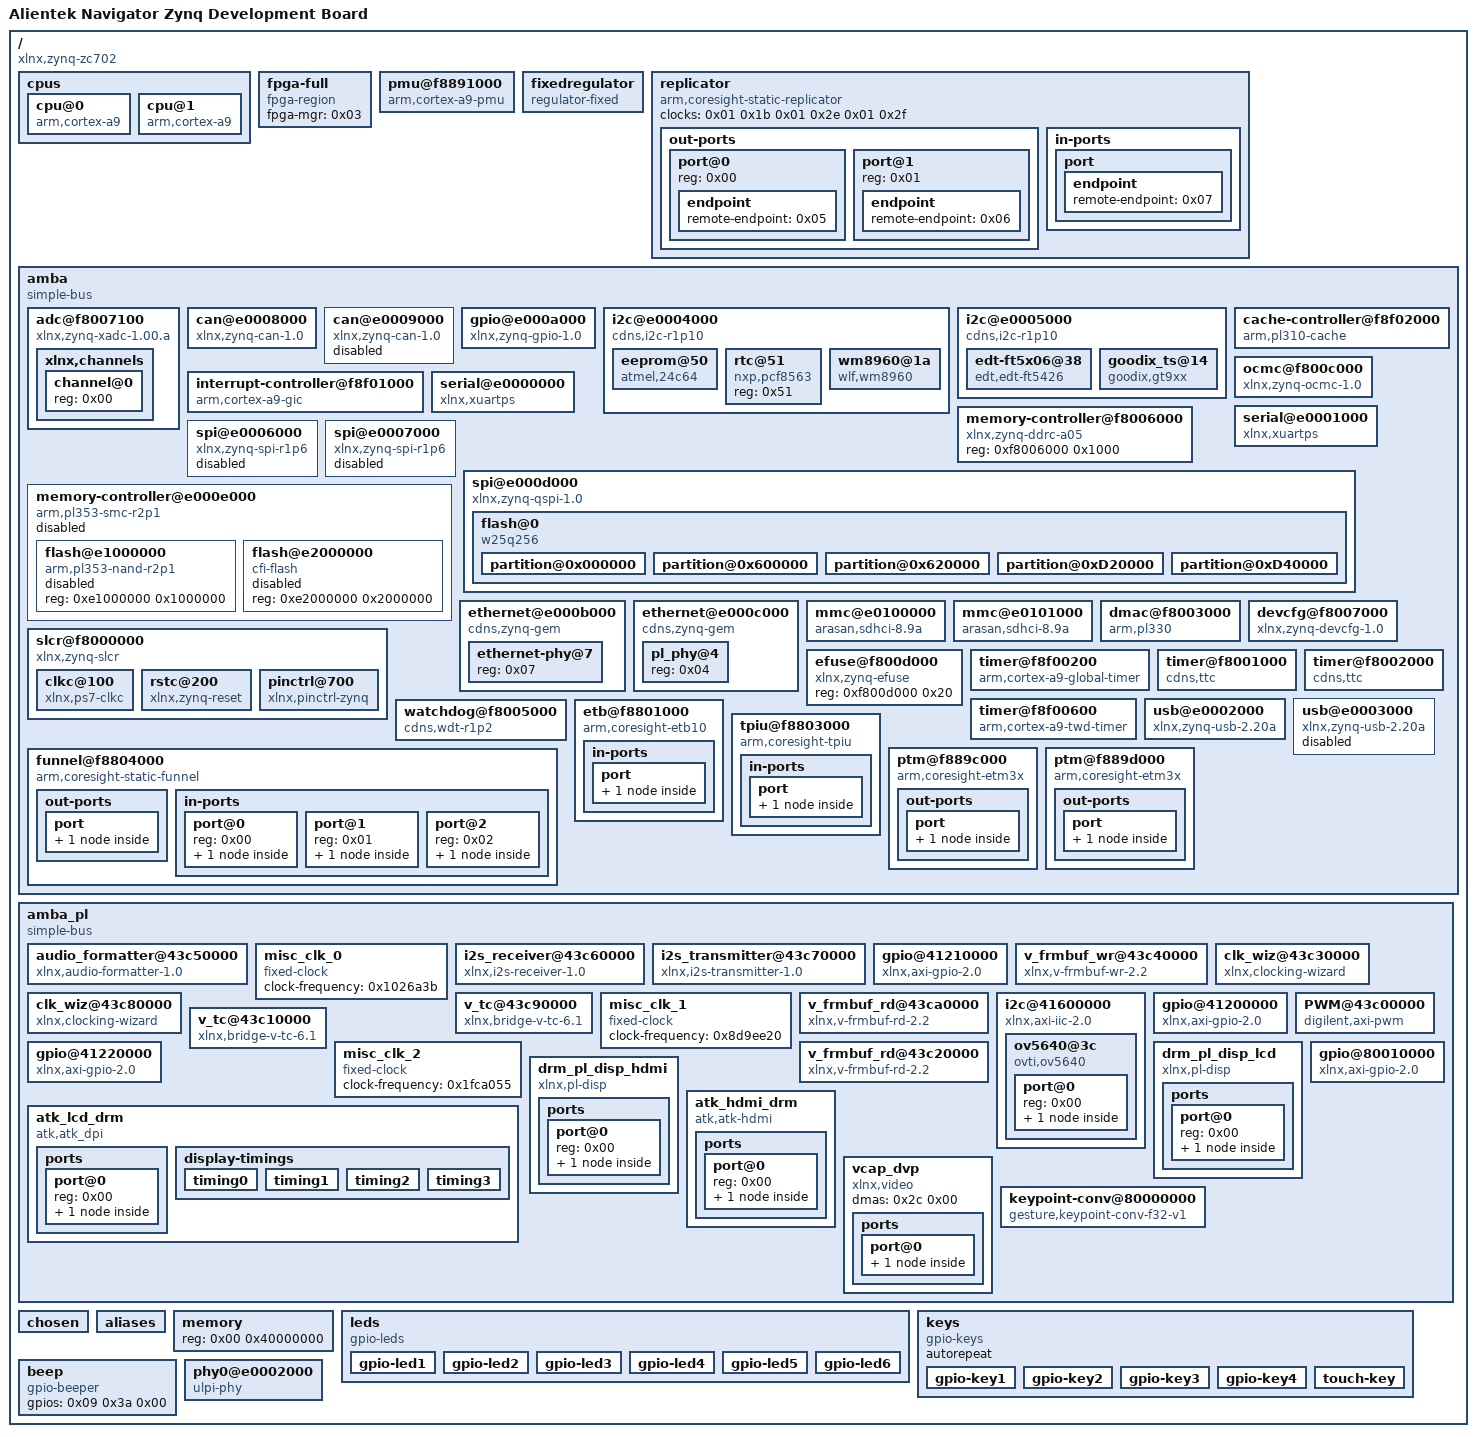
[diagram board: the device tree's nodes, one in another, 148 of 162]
/dts-v1/;

/ {
	#address-cells = <0x01>;
	#size-cells = <0x01>;
	compatible = "xlnx,zynq-zc702\0xlnx,zynq-7000";
	model = "Alientek Navigator Zynq Development Board";

	cpus {
		#address-cells = <0x01>;
		#size-cells = <0x00>;

		cpu@0 {
			compatible = "arm,cortex-a9";
			device_type = "cpu";
			reg = <0x00>;
			clocks = <0x01 0x03>;
			clock-latency = <0x3e8>;
			cpu0-supply = <0x02>;
			operating-points = <0xbb2ca 0xf4240 0x5d965 0xf4240>;
			phandle = <0x13>;
		};

		cpu@1 {
			compatible = "arm,cortex-a9";
			device_type = "cpu";
			reg = <0x01>;
			clocks = <0x01 0x03>;
			phandle = <0x15>;
		};
	};

	fpga-full {
		compatible = "fpga-region";
		fpga-mgr = <0x03>;
		#address-cells = <0x01>;
		#size-cells = <0x01>;
		ranges;
		phandle = <0x2f>;
	};

	pmu@f8891000 {
		compatible = "arm,cortex-a9-pmu";
		interrupts = <0x00 0x05 0x04 0x00 0x06 0x04>;
		interrupt-parent = <0x04>;
		reg = <0xf8891000 0x1000 0xf8893000 0x1000>;
	};

	fixedregulator {
		compatible = "regulator-fixed";
		regulator-name = "VCCPINT";
		regulator-min-microvolt = <0xf4240>;
		regulator-max-microvolt = <0xf4240>;
		regulator-boot-on;
		regulator-always-on;
		phandle = <0x02>;
	};

	replicator {
		compatible = "arm,coresight-static-replicator";
		clocks = <0x01 0x1b 0x01 0x2e 0x01 0x2f>;
		clock-names = "apb_pclk\0dbg_trc\0dbg_apb";

		out-ports {
			#address-cells = <0x01>;
			#size-cells = <0x00>;

			port@0 {
				reg = <0x00>;

				endpoint {
					remote-endpoint = <0x05>;
					phandle = <0x0f>;
				};
			};

			port@1 {
				reg = <0x01>;

				endpoint {
					remote-endpoint = <0x06>;
					phandle = <0x0e>;
				};
			};
		};

		in-ports {

			port {

				endpoint {
					remote-endpoint = <0x07>;
					phandle = <0x10>;
				};
			};
		};
	};

	amba {
		u-boot,dm-pre-reloc;
		compatible = "simple-bus";
		#address-cells = <0x01>;
		#size-cells = <0x01>;
		interrupt-parent = <0x04>;
		ranges;
		phandle = <0x30>;

		adc@f8007100 {
			compatible = "xlnx,zynq-xadc-1.00.a";
			reg = <0xf8007100 0x20>;
			interrupts = <0x00 0x07 0x04>;
			interrupt-parent = <0x04>;
			clocks = <0x01 0x0c>;
			status = "okay";
			phandle = <0x31>;

			xlnx,channels {
				#address-cells = <0x01>;
				#size-cells = <0x00>;

				channel@0 {
					reg = <0x00>;
				};
			};
		};

		can@e0008000 {
			compatible = "xlnx,zynq-can-1.0";
			status = "okay";
			clocks = <0x01 0x13 0x01 0x24>;
			clock-names = "can_clk\0pclk";
			reg = <0xe0008000 0x1000>;
			interrupts = <0x00 0x1c 0x04>;
			interrupt-parent = <0x04>;
			tx-fifo-depth = <0x40>;
			rx-fifo-depth = <0x40>;
			phandle = <0x32>;
		};

		can@e0009000 {
			compatible = "xlnx,zynq-can-1.0";
			status = "disabled";
			clocks = <0x01 0x14 0x01 0x25>;
			clock-names = "can_clk\0pclk";
			reg = <0xe0009000 0x1000>;
			interrupts = <0x00 0x33 0x04>;
			interrupt-parent = <0x04>;
			tx-fifo-depth = <0x40>;
			rx-fifo-depth = <0x40>;
			phandle = <0x33>;
		};

		gpio@e000a000 {
			compatible = "xlnx,zynq-gpio-1.0";
			#gpio-cells = <0x02>;
			clocks = <0x01 0x2a>;
			gpio-controller;
			interrupt-controller;
			#interrupt-cells = <0x02>;
			interrupt-parent = <0x04>;
			interrupts = <0x00 0x14 0x04>;
			reg = <0xe000a000 0x1000>;
			emio-gpio-width = <0x0b>;
			gpio-mask-high = <0x00>;
			gpio-mask-low = <0x5600>;
			phandle = <0x09>;
		};

		i2c@e0004000 {
			compatible = "cdns,i2c-r1p10";
			status = "okay";
			clocks = <0x01 0x26>;
			interrupt-parent = <0x04>;
			interrupts = <0x00 0x19 0x04>;
			reg = <0xe0004000 0x1000>;
			#address-cells = <0x01>;
			#size-cells = <0x00>;
			clock-frequency = <0x186a0>;
			phandle = <0x34>;

			eeprom@50 {
				compatible = "atmel,24c64";
				reg = <0x50>;
				pagesize = <0x20>;
			};

			rtc@51 {
				compatible = "nxp,pcf8563";
				reg = <0x51>;
			};

			wm8960@1a {
				compatible = "wlf,wm8960";
				reg = <0x1a>;
				#sound-dai-cells = <0x00>;
				wlf,shared-lrclk;
				clock-names = "mclk";
				clocks = <0x08 0x01>;
				phandle = <0x1a>;
			};
		};

		i2c@e0005000 {
			compatible = "cdns,i2c-r1p10";
			status = "okay";
			clocks = <0x01 0x27>;
			interrupt-parent = <0x04>;
			interrupts = <0x00 0x30 0x04>;
			reg = <0xe0005000 0x1000>;
			#address-cells = <0x01>;
			#size-cells = <0x00>;
			clock-frequency = <0x186a0>;
			phandle = <0x2a>;

			edt-ft5x06@38 {
				compatible = "edt,edt-ft5426";
				reg = <0x38>;
				interrupt-parent = <0x09>;
				interrupts = <0x3c 0x02>;
				reset-gpio = <0x09 0x3b 0x01>;
				interrupt-gpio = <0x09 0x3c 0x01>;
			};

			goodix_ts@14 {
				compatible = "goodix,gt9xx";
				status = "okay";
				reg = <0x14>;
				interrupt-parent = <0x09>;
				interrupts = <0x3c 0x00>;
				reset-gpio = <0x09 0x3b 0x01>;
				interrupt-gpio = <0x09 0x3c 0x01>;
			};
		};

		interrupt-controller@f8f01000 {
			compatible = "arm,cortex-a9-gic";
			#interrupt-cells = <0x03>;
			interrupt-controller;
			reg = <0xf8f01000 0x1000 0xf8f00100 0x100>;
			num_cpus = <0x02>;
			num_interrupts = <0x60>;
			phandle = <0x04>;
		};

		cache-controller@f8f02000 {
			compatible = "arm,pl310-cache";
			reg = <0xf8f02000 0x1000>;
			interrupts = <0x00 0x02 0x04>;
			arm,data-latency = <0x03 0x02 0x02>;
			arm,tag-latency = <0x02 0x02 0x02>;
			cache-unified;
			cache-level = <0x02>;
			phandle = <0x35>;
		};

		memory-controller@f8006000 {
			compatible = "xlnx,zynq-ddrc-a05";
			reg = <0xf8006000 0x1000>;
			phandle = <0x36>;
		};

		ocmc@f800c000 {
			compatible = "xlnx,zynq-ocmc-1.0";
			interrupt-parent = <0x04>;
			interrupts = <0x00 0x03 0x04>;
			reg = <0xf800c000 0x1000>;
			phandle = <0x37>;
		};

		serial@e0000000 {
			compatible = "xlnx,xuartps\0cdns,uart-r1p8";
			status = "okay";
			clocks = <0x01 0x17 0x01 0x28>;
			clock-names = "uart_clk\0pclk";
			reg = <0xe0000000 0x1000>;
			interrupts = <0x00 0x1b 0x04>;
			cts-override;
			device_type = "serial";
			port-number = <0x00>;
			u-boot,dm-pre-reloc;
			phandle = <0x38>;
		};

		serial@e0001000 {
			compatible = "xlnx,xuartps\0cdns,uart-r1p8";
			status = "okay";
			clocks = <0x01 0x18 0x01 0x29>;
			clock-names = "uart_clk\0pclk";
			reg = <0xe0001000 0x1000>;
			interrupts = <0x00 0x32 0x04>;
			cts-override;
			device_type = "serial";
			port-number = <0x01>;
			phandle = <0x39>;
		};

		spi@e0006000 {
			compatible = "xlnx,zynq-spi-r1p6";
			reg = <0xe0006000 0x1000>;
			status = "disabled";
			interrupt-parent = <0x04>;
			interrupts = <0x00 0x1a 0x04>;
			clocks = <0x01 0x19 0x01 0x22>;
			clock-names = "ref_clk\0pclk";
			#address-cells = <0x01>;
			#size-cells = <0x00>;
			phandle = <0x3a>;
		};

		spi@e0007000 {
			compatible = "xlnx,zynq-spi-r1p6";
			reg = <0xe0007000 0x1000>;
			status = "disabled";
			interrupt-parent = <0x04>;
			interrupts = <0x00 0x31 0x04>;
			clocks = <0x01 0x1a 0x01 0x23>;
			clock-names = "ref_clk\0pclk";
			#address-cells = <0x01>;
			#size-cells = <0x00>;
			phandle = <0x3b>;
		};

		spi@e000d000 {
			clock-names = "ref_clk\0pclk";
			clocks = <0x01 0x0a 0x01 0x2b>;
			compatible = "xlnx,zynq-qspi-1.0";
			status = "okay";
			interrupt-parent = <0x04>;
			interrupts = <0x00 0x13 0x04>;
			reg = <0xe000d000 0x1000>;
			#address-cells = <0x01>;
			#size-cells = <0x00>;
			is-dual = <0x00>;
			num-cs = <0x01>;
			spi-rx-bus-width = <0x04>;
			spi-tx-bus-width = <0x04>;
			u-boot,dm-pre-reloc;
			phandle = <0x3c>;

			flash@0 {
				compatible = "w25q256\0jedec,spi-nor";
				reg = <0x00>;
				spi-max-frequency = <0x2faf080>;
				#address-cells = <0x01>;
				#size-cells = <0x01>;

				partition@0x000000 {
					label = "boot";
					reg = <0x00 0x600000>;
				};

				partition@0x600000 {
					label = "bootenv";
					reg = <0x600000 0x20000>;
				};

				partition@0x620000 {
					label = "image.ub";
					reg = <0x620000 0x700000>;
				};

				partition@0xD20000 {
					label = "boot.scr";
					reg = <0xd20000 0x20000>;
				};

				partition@0xD40000 {
					label = "space";
					reg = <0xd40000 0x00>;
				};
			};
		};

		memory-controller@e000e000 {
			#address-cells = <0x01>;
			#size-cells = <0x01>;
			status = "disabled";
			clock-names = "memclk\0apb_pclk";
			clocks = <0x01 0x0b 0x01 0x2c>;
			compatible = "arm,pl353-smc-r2p1\0arm,primecell";
			interrupt-parent = <0x04>;
			interrupts = <0x00 0x12 0x04>;
			ranges;
			reg = <0xe000e000 0x1000>;
			phandle = <0x3d>;

			flash@e1000000 {
				status = "disabled";
				compatible = "arm,pl353-nand-r2p1";
				reg = <0xe1000000 0x1000000>;
				#address-cells = <0x01>;
				#size-cells = <0x01>;
				phandle = <0x3e>;
			};

			flash@e2000000 {
				status = "disabled";
				compatible = "cfi-flash";
				reg = <0xe2000000 0x2000000>;
				#address-cells = <0x01>;
				#size-cells = <0x01>;
				phandle = <0x3f>;
			};
		};

		ethernet@e000b000 {
			compatible = "cdns,zynq-gem\0cdns,gem";
			reg = <0xe000b000 0x1000>;
			status = "okay";
			interrupts = <0x00 0x16 0x04>;
			clocks = <0x01 0x1e 0x01 0x1e 0x01 0x0d>;
			clock-names = "pclk\0hclk\0tx_clk";
			#address-cells = <0x01>;
			#size-cells = <0x00>;
			phy-mode = "rgmii-id";
			xlnx,ptp-enet-clock = <0x79dbbf3>;
			local-mac-address = [00 0a 35 00 8b 87];
			phy-handle = <0x0a>;
			phandle = <0x40>;

			ethernet-phy@7 {
				reg = <0x07>;
				device_type = "ethernet-phy";
				phandle = <0x0a>;
			};
		};

		ethernet@e000c000 {
			compatible = "cdns,zynq-gem\0cdns,gem";
			reg = <0xe000c000 0x1000>;
			status = "okay";
			interrupts = <0x00 0x2d 0x04>;
			clocks = <0x01 0x1f 0x01 0x1f 0x01 0x0e>;
			clock-names = "pclk\0hclk\0tx_clk";
			#address-cells = <0x01>;
			#size-cells = <0x00>;
			phy-mode = "gmii";
			xlnx,ptp-enet-clock = <0x79dbbf3>;
			local-mac-address = [00 0a 35 00 11 55];
			phy-reset-gpio = <0x09 0x3f 0x01>;
			phy-reset-active-low;
			phy-handle = <0x0b>;
			phandle = <0x41>;

			pl_phy@4 {
				reg = <0x04>;
				device_type = "ethernet-phy";
				phandle = <0x0b>;
			};
		};

		mmc@e0100000 {
			compatible = "arasan,sdhci-8.9a";
			status = "okay";
			clock-names = "clk_xin\0clk_ahb";
			clocks = <0x01 0x15 0x01 0x20>;
			interrupt-parent = <0x04>;
			interrupts = <0x00 0x18 0x04>;
			reg = <0xe0100000 0x1000>;
			xlnx,has-cd = <0x01>;
			xlnx,has-power = <0x00>;
			xlnx,has-wp = <0x00>;
			u-boot,dm-pre-reloc;
			phandle = <0x42>;
		};

		mmc@e0101000 {
			compatible = "arasan,sdhci-8.9a";
			status = "okay";
			clock-names = "clk_xin\0clk_ahb";
			clocks = <0x01 0x16 0x01 0x21>;
			interrupt-parent = <0x04>;
			interrupts = <0x00 0x2f 0x04>;
			reg = <0xe0101000 0x1000>;
			xlnx,has-cd = <0x00>;
			xlnx,has-power = <0x00>;
			xlnx,has-wp = <0x00>;
			phandle = <0x43>;
		};

		slcr@f8000000 {
			u-boot,dm-pre-reloc;
			#address-cells = <0x01>;
			#size-cells = <0x01>;
			compatible = "xlnx,zynq-slcr\0syscon\0simple-mfd";
			reg = <0xf8000000 0x1000>;
			ranges;
			phandle = <0x0c>;

			clkc@100 {
				u-boot,dm-pre-reloc;
				#clock-cells = <0x01>;
				compatible = "xlnx,ps7-clkc";
				fclk-enable = <0x07>;
				clock-output-names = "armpll\0ddrpll\0iopll\0cpu_6or4x\0cpu_3or2x\0cpu_2x\0cpu_1x\0ddr2x\0ddr3x\0dci\0lqspi\0smc\0pcap\0gem0\0gem1\0fclk0\0fclk1\0fclk2\0fclk3\0can0\0can1\0sdio0\0sdio1\0uart0\0uart1\0spi0\0spi1\0dma\0usb0_aper\0usb1_aper\0gem0_aper\0gem1_aper\0sdio0_aper\0sdio1_aper\0spi0_aper\0spi1_aper\0can0_aper\0can1_aper\0i2c0_aper\0i2c1_aper\0uart0_aper\0uart1_aper\0gpio_aper\0lqspi_aper\0smc_aper\0swdt\0dbg_trc\0dbg_apb";
				reg = <0x100 0x100>;
				ps-clk-frequency = <0x1fca055>;
				phandle = <0x01>;
			};

			rstc@200 {
				compatible = "xlnx,zynq-reset";
				reg = <0x200 0x48>;
				#reset-cells = <0x01>;
				syscon = <0x0c>;
				phandle = <0x44>;
			};

			pinctrl@700 {
				compatible = "xlnx,pinctrl-zynq";
				reg = <0x700 0x200>;
				syscon = <0x0c>;
				phandle = <0x45>;
			};
		};

		dmac@f8003000 {
			compatible = "arm,pl330\0arm,primecell";
			reg = <0xf8003000 0x1000>;
			interrupt-parent = <0x04>;
			interrupt-names = "abort\0dma0\0dma1\0dma2\0dma3\0dma4\0dma5\0dma6\0dma7";
			interrupts = <0x00 0x0d 0x04 0x00 0x0e 0x04 0x00 0x0f 0x04 0x00 0x10 0x04 0x00 0x11 0x04 0x00 0x28 0x04 0x00 0x29 0x04 0x00 0x2a 0x04 0x00 0x2b 0x04>;
			#dma-cells = <0x01>;
			#dma-channels = <0x08>;
			#dma-requests = <0x04>;
			clocks = <0x01 0x1b>;
			clock-names = "apb_pclk";
			phandle = <0x46>;
		};

		devcfg@f8007000 {
			compatible = "xlnx,zynq-devcfg-1.0";
			interrupt-parent = <0x04>;
			interrupts = <0x00 0x08 0x04>;
			reg = <0xf8007000 0x100>;
			clocks = <0x01 0x0c 0x01 0x0f 0x01 0x10 0x01 0x11 0x01 0x12>;
			clock-names = "ref_clk\0fclk0\0fclk1\0fclk2\0fclk3";
			syscon = <0x0c>;
			phandle = <0x03>;
		};

		efuse@f800d000 {
			compatible = "xlnx,zynq-efuse";
			reg = <0xf800d000 0x20>;
			phandle = <0x47>;
		};

		timer@f8f00200 {
			compatible = "arm,cortex-a9-global-timer";
			reg = <0xf8f00200 0x20>;
			interrupts = <0x01 0x0b 0x301>;
			interrupt-parent = <0x04>;
			clocks = <0x01 0x04>;
			phandle = <0x48>;
		};

		timer@f8001000 {
			interrupt-parent = <0x04>;
			interrupts = <0x00 0x0a 0x04 0x00 0x0b 0x04 0x00 0x0c 0x04>;
			compatible = "cdns,ttc";
			clocks = <0x01 0x06>;
			reg = <0xf8001000 0x1000>;
			phandle = <0x49>;
		};

		timer@f8002000 {
			interrupt-parent = <0x04>;
			interrupts = <0x00 0x25 0x04 0x00 0x26 0x04 0x00 0x27 0x04>;
			compatible = "cdns,ttc";
			clocks = <0x01 0x06>;
			reg = <0xf8002000 0x1000>;
			phandle = <0x4a>;
		};

		timer@f8f00600 {
			interrupt-parent = <0x04>;
			interrupts = <0x01 0x0d 0x301>;
			compatible = "arm,cortex-a9-twd-timer";
			reg = <0xf8f00600 0x20>;
			clocks = <0x01 0x04>;
			phandle = <0x4b>;
		};

		usb@e0002000 {
			compatible = "xlnx,zynq-usb-2.20a\0chipidea,usb2";
			status = "okay";
			clocks = <0x01 0x1c>;
			interrupt-parent = <0x04>;
			interrupts = <0x00 0x15 0x04>;
			reg = <0xe0002000 0x1000>;
			phy_type = "ulpi";
			usb-reset = <0x09 0x09 0x00>;
			dr_mode = "otg";
			usb-phy = <0x0d>;
			phandle = <0x4c>;
		};

		usb@e0003000 {
			compatible = "xlnx,zynq-usb-2.20a\0chipidea,usb2";
			status = "disabled";
			clocks = <0x01 0x1d>;
			interrupt-parent = <0x04>;
			interrupts = <0x00 0x2c 0x04>;
			reg = <0xe0003000 0x1000>;
			phy_type = "ulpi";
			phandle = <0x4d>;
		};

		watchdog@f8005000 {
			clocks = <0x01 0x2d>;
			compatible = "cdns,wdt-r1p2";
			interrupt-parent = <0x04>;
			interrupts = <0x00 0x09 0x01>;
			reg = <0xf8005000 0x1000>;
			timeout-sec = <0x0a>;
			status = "okay";
			reset-on-timeout;
			phandle = <0x4e>;
		};

		etb@f8801000 {
			compatible = "arm,coresight-etb10\0arm,primecell";
			reg = <0xf8801000 0x1000>;
			clocks = <0x01 0x1b 0x01 0x2e 0x01 0x2f>;
			clock-names = "apb_pclk\0dbg_trc\0dbg_apb";

			in-ports {

				port {

					endpoint {
						remote-endpoint = <0x0e>;
						phandle = <0x06>;
					};
				};
			};
		};

		tpiu@f8803000 {
			compatible = "arm,coresight-tpiu\0arm,primecell";
			reg = <0xf8803000 0x1000>;
			clocks = <0x01 0x1b 0x01 0x2e 0x01 0x2f>;
			clock-names = "apb_pclk\0dbg_trc\0dbg_apb";

			in-ports {

				port {

					endpoint {
						remote-endpoint = <0x0f>;
						phandle = <0x05>;
					};
				};
			};
		};

		funnel@f8804000 {
			compatible = "arm,coresight-static-funnel\0arm,primecell";
			reg = <0xf8804000 0x1000>;
			clocks = <0x01 0x1b 0x01 0x2e 0x01 0x2f>;
			clock-names = "apb_pclk\0dbg_trc\0dbg_apb";

			out-ports {

				port {

					endpoint {
						remote-endpoint = <0x10>;
						phandle = <0x07>;
					};
				};
			};

			in-ports {
				#address-cells = <0x01>;
				#size-cells = <0x00>;

				port@0 {
					reg = <0x00>;

					endpoint {
						remote-endpoint = <0x11>;
						phandle = <0x14>;
					};
				};

				port@1 {
					reg = <0x01>;

					endpoint {
						remote-endpoint = <0x12>;
						phandle = <0x16>;
					};
				};

				port@2 {
					reg = <0x02>;

					endpoint {
						phandle = <0x4f>;
					};
				};
			};
		};

		ptm@f889c000 {
			compatible = "arm,coresight-etm3x\0arm,primecell";
			reg = <0xf889c000 0x1000>;
			clocks = <0x01 0x1b 0x01 0x2e 0x01 0x2f>;
			clock-names = "apb_pclk\0dbg_trc\0dbg_apb";
			cpu = <0x13>;

			out-ports {

				port {

					endpoint {
						remote-endpoint = <0x14>;
						phandle = <0x11>;
					};
				};
			};
		};

		ptm@f889d000 {
			compatible = "arm,coresight-etm3x\0arm,primecell";
			reg = <0xf889d000 0x1000>;
			clocks = <0x01 0x1b 0x01 0x2e 0x01 0x2f>;
			clock-names = "apb_pclk\0dbg_trc\0dbg_apb";
			cpu = <0x15>;

			out-ports {

				port {

					endpoint {
						remote-endpoint = <0x16>;
						phandle = <0x12>;
					};
				};
			};
		};
	};

	amba_pl {
		#address-cells = <0x01>;
		#size-cells = <0x01>;
		compatible = "simple-bus";
		ranges;
		phandle = <0x50>;

		audio_formatter@43c50000 {
			clock-names = "s_axi_lite_aclk\0m_axis_mm2s_aclk\0aud_mclk\0s_axis_s2mm_aclk";
			clocks = <0x01 0x0f 0x01 0x0f 0x17 0x01 0x0f>;
			compatible = "xlnx,audio-formatter-1.0\0xlnx,audio-formatter-1.0";
			interrupt-names = "irq_mm2s\0irq_s2mm";
			interrupt-parent = <0x04>;
			interrupts = <0x00 0x24 0x04 0x00 0x21 0x04>;
			reg = <0x43c50000 0x10000>;
			xlnx,include-mm2s = <0x01>;
			xlnx,include-s2mm = <0x01>;
			xlnx,max-num-channels-mm2s = <0x02>;
			xlnx,max-num-channels-s2mm = <0x02>;
			xlnx,mm2s-addr-width = <0x20>;
			xlnx,mm2s-async-clock = <0x00>;
			xlnx,mm2s-dataformat = <0x03>;
			xlnx,packing-mode-mm2s = <0x00>;
			xlnx,packing-mode-s2mm = <0x00>;
			xlnx,rx = <0x18>;
			xlnx,s2mm-addr-width = <0x20>;
			xlnx,s2mm-async-clock = <0x00>;
			xlnx,s2mm-dataformat = <0x01>;
			xlnx,tx = <0x19>;
			audio-codec = <0x1a>;
			phandle = <0x1b>;
		};

		misc_clk_0 {
			#clock-cells = <0x00>;
			clock-frequency = <0x1026a3b>;
			compatible = "fixed-clock";
			phandle = <0x17>;
		};

		i2s_receiver@43c60000 {
			aud_mclk = <0x1026a3b>;
			clock-names = "s_axi_ctrl_aclk\0aud_mclk\0m_axis_aud_aclk";
			clocks = <0x01 0x0f 0x17 0x01 0x0f>;
			compatible = "xlnx,i2s-receiver-1.0\0xlnx,i2s-receiver-1.0";
			interrupt-names = "irq";
			interrupt-parent = <0x04>;
			interrupts = <0x00 0x23 0x04>;
			reg = <0x43c60000 0x10000>;
			xlnx,depth = <0x80>;
			xlnx,dwidth = <0x18>;
			xlnx,num-channels = <0x01>;
			xlnx,snd-pcm = <0x1b>;
			phandle = <0x18>;
		};

		i2s_transmitter@43c70000 {
			aud_mclk = <0x1026a3b>;
			clock-names = "s_axi_ctrl_aclk\0aud_mclk\0s_axis_aud_aclk";
			clocks = <0x01 0x0f 0x17 0x01 0x0f>;
			compatible = "xlnx,i2s-transmitter-1.0\0xlnx,i2s-transmitter-1.0";
			interrupt-names = "irq";
			interrupt-parent = <0x04>;
			interrupts = <0x00 0x22 0x04>;
			reg = <0x43c70000 0x10000>;
			xlnx,depth = <0x80>;
			xlnx,dwidth = <0x18>;
			xlnx,num-channels = <0x01>;
			xlnx,snd-pcm = <0x1b>;
			phandle = <0x19>;
		};

		gpio@41210000 {
			#gpio-cells = <0x03>;
			clock-names = "s_axi_aclk";
			clocks = <0x01 0x0f>;
			compatible = "xlnx,axi-gpio-2.0\0xlnx,xps-gpio-1.00.a";
			gpio-controller;
			reg = <0x41210000 0x10000>;
			xlnx,all-inputs = <0x00>;
			xlnx,all-inputs-2 = <0x00>;
			xlnx,all-outputs = <0x01>;
			xlnx,all-outputs-2 = <0x00>;
			xlnx,dout-default = <0x00>;
			xlnx,dout-default-2 = <0x00>;
			xlnx,gpio-width = <0x02>;
			xlnx,gpio2-width = <0x20>;
			xlnx,interrupt-present = <0x00>;
			xlnx,is-dual = <0x00>;
			xlnx,tri-default = <0xffffffff>;
			xlnx,tri-default-2 = <0xffffffff>;
			phandle = <0x2e>;
		};

		v_frmbuf_wr@43c40000 {
			#dma-cells = <0x01>;
			clock-names = "ap_clk";
			clocks = <0x01 0x10>;
			compatible = "xlnx,v-frmbuf-wr-2.2\0xlnx,axi-frmbuf-wr-v2.1";
			interrupt-names = "interrupt";
			interrupt-parent = <0x04>;
			interrupts = <0x00 0x1f 0x04>;
			reg = <0x43c40000 0x10000>;
			reset-gpios = <0x1c 0x01 0x00 0x01>;
			xlnx,dma-addr-width = <0x20>;
			xlnx,dma-align = <0x08>;
			xlnx,max-height = <0x438>;
			xlnx,max-width = <0x780>;
			xlnx,pixels-per-clock = <0x01>;
			xlnx,s-axi-ctrl-addr-width = <0x07>;
			xlnx,s-axi-ctrl-data-width = <0x20>;
			xlnx,vid-formats = "rgb888\0bgr888";
			xlnx,video-width = <0x08>;
			phandle = <0x2c>;
		};

		clk_wiz@43c30000 {
			#clock-cells = <0x01>;
			clock-names = "s_axi_aclk\0clk_in1";
			clock-output-names = "0x43c30000-lcd_pclk", "0x43c30000-mclk";
			clocks = <0x01 0x0f 0x01 0x0f>;
			compatible = "xlnx,clocking-wizard";
			reg = <0x43c30000 0x10000>;
			speed-grade = <0x02>;
			xlnx,nr-outputs = <0x02>;
			phandle = <0x08>;
		};

		clk_wiz@43c80000 {
			#clock-cells = <0x01>;
			clock-names = "s_axi_aclk\0clk_in1";
			clock-output-names = "0x43c80000-hdmi_pclk", "0x43c80000-hdmi_pclk_5x";
			clocks = <0x01 0x0f 0x01 0x0f>;
			compatible = "xlnx,clocking-wizard";
			reg = <0x43c80000 0x10000>;
			speed-grade = <0x02>;
			xlnx,nr-outputs = <0x02>;
			phandle = <0x29>;
		};

		v_tc@43c90000 {
			clock-names = "clk\0s_axi_aclk";
			clocks = <0x1d 0x01 0x0f>;
			compatible = "xlnx,bridge-v-tc-6.1";
			interrupt-names = "irq";
			interrupt-parent = <0x04>;
			interrupts = <0x00 0x35 0x04>;
			reg = <0x43c90000 0x10000>;
			xlnx,generator;
			xlnx,pixels-per-clock = <0x01>;
			phandle = <0x27>;
		};

		misc_clk_1 {
			#clock-cells = <0x00>;
			clock-frequency = <0x8d9ee20>;
			compatible = "fixed-clock";
			phandle = <0x1d>;
		};

		v_frmbuf_rd@43ca0000 {
			#dma-cells = <0x01>;
			clock-names = "ap_clk";
			clocks = <0x1d>;
			compatible = "xlnx,v-frmbuf-rd-2.2\0xlnx,axi-frmbuf-rd-v2.1";
			interrupt-names = "interrupt";
			interrupt-parent = <0x04>;
			interrupts = <0x00 0x34 0x04>;
			reg = <0x43ca0000 0x10000>;
			reset-gpios = <0x1c 0x02 0x00 0x01>;
			xlnx,dma-addr-width = <0x20>;
			xlnx,dma-align = <0x08>;
			xlnx,max-height = <0x438>;
			xlnx,max-width = <0x780>;
			xlnx,pixels-per-clock = <0x01>;
			xlnx,s-axi-ctrl-addr-width = <0x07>;
			xlnx,s-axi-ctrl-data-width = <0x20>;
			xlnx,vid-formats = "rgb888\0bgr888";
			xlnx,video-width = <0x08>;
			phandle = <0x26>;
		};

		i2c@41600000 {
			#address-cells = <0x01>;
			#size-cells = <0x00>;
			clock-names = "s_axi_aclk";
			clocks = <0x01 0x0f>;
			compatible = "xlnx,axi-iic-2.0\0xlnx,xps-iic-2.00.a";
			interrupt-names = "iic2intc_irpt";
			interrupt-parent = <0x04>;
			interrupts = <0x00 0x20 0x04>;
			reg = <0x41600000 0x10000>;
			clock-frequency = <0x186a0>;
			phandle = <0x51>;

			ov5640@3c {
				compatible = "ovti,ov5640";
				reg = <0x3c>;
				pwdn-gpios = <0x09 0x3d 0x00>;
				reset-gpios = <0x09 0x3e 0x01>;
				status = "okay";
				#address-cells = <0x01>;
				#size-cells = <0x00>;

				port@0 {
					reg = <0x00>;

					endpoint {
						remote-endpoint = <0x1e>;
						phandle = <0x2d>;
					};
				};
			};
		};

		gpio@41200000 {
			#gpio-cells = <0x03>;
			clock-names = "s_axi_aclk";
			clocks = <0x01 0x0f>;
			compatible = "xlnx,axi-gpio-2.0\0xlnx,xps-gpio-1.00.a";
			gpio-controller;
			reg = <0x41200000 0x10000>;
			xlnx,all-inputs = <0x00>;
			xlnx,all-inputs-2 = <0x00>;
			xlnx,all-outputs = <0x00>;
			xlnx,all-outputs-2 = <0x00>;
			xlnx,dout-default = <0x00>;
			xlnx,dout-default-2 = <0x00>;
			xlnx,gpio-width = <0x03>;
			xlnx,gpio2-width = <0x20>;
			xlnx,interrupt-present = <0x00>;
			xlnx,is-dual = <0x00>;
			xlnx,tri-default = <0xffffffff>;
			xlnx,tri-default-2 = <0xffffffff>;
			phandle = <0x24>;
		};

		PWM@43c00000 {
			clock-names = "pwm";
			clocks = <0x01 0x0f>;
			compatible = "digilent,axi-pwm";
			reg = <0x43c00000 0x10000>;
			xlnx,pwm-axi-addr-width = <0x07>;
			xlnx,pwm-axi-data-width = <0x20>;
			#pwm-cells = <0x02>;
			npwm = <0x01>;
			phandle = <0x23>;
		};

		v_tc@43c10000 {
			clock-names = "clk\0s_axi_aclk";
			clocks = <0x1f 0x01 0x0f>;
			compatible = "xlnx,bridge-v-tc-6.1";
			interrupt-names = "irq";
			interrupt-parent = <0x04>;
			interrupts = <0x00 0x1e 0x04>;
			reg = <0x43c10000 0x10000>;
			xlnx,generator;
			xlnx,pixels-per-clock = <0x01>;
			phandle = <0x21>;
		};

		misc_clk_2 {
			#clock-cells = <0x00>;
			clock-frequency = <0x1fca055>;
			compatible = "fixed-clock";
			phandle = <0x1f>;
		};

		v_frmbuf_rd@43c20000 {
			#dma-cells = <0x01>;
			clock-names = "ap_clk";
			clocks = <0x1f>;
			compatible = "xlnx,v-frmbuf-rd-2.2\0xlnx,axi-frmbuf-rd-v2.1";
			interrupt-names = "interrupt";
			interrupt-parent = <0x04>;
			interrupts = <0x00 0x1d 0x04>;
			reg = <0x43c20000 0x10000>;
			reset-gpios = <0x1c 0x00 0x00 0x01>;
			xlnx,dma-addr-width = <0x20>;
			xlnx,dma-align = <0x08>;
			xlnx,max-height = <0x438>;
			xlnx,max-width = <0x780>;
			xlnx,pixels-per-clock = <0x01>;
			xlnx,s-axi-ctrl-addr-width = <0x07>;
			xlnx,s-axi-ctrl-data-width = <0x20>;
			xlnx,vid-formats = "rgb888\0bgr888";
			xlnx,video-width = <0x08>;
			phandle = <0x20>;
		};

		gpio@41220000 {
			#gpio-cells = <0x03>;
			clock-names = "s_axi_aclk";
			clocks = <0x01 0x0f>;
			compatible = "xlnx,axi-gpio-2.0\0xlnx,xps-gpio-1.00.a";
			gpio-controller;
			reg = <0x41220000 0x10000>;
			xlnx,all-inputs = <0x00>;
			xlnx,all-inputs-2 = <0x00>;
			xlnx,all-outputs = <0x01>;
			xlnx,all-outputs-2 = <0x00>;
			xlnx,dout-default = <0x00>;
			xlnx,dout-default-2 = <0x00>;
			xlnx,gpio-width = <0x03>;
			xlnx,gpio2-width = <0x20>;
			xlnx,interrupt-present = <0x00>;
			xlnx,is-dual = <0x00>;
			xlnx,tri-default = <0xffffffff>;
			xlnx,tri-default-2 = <0xffffffff>;
			phandle = <0x1c>;
		};

		drm_pl_disp_lcd {
			compatible = "xlnx,pl-disp";
			dmas = <0x20 0x00>;
			dma-names = "dma0";
			xlnx,vformat = "BG24";
			xlnx,bridge = <0x21>;

			ports {
				#address-cells = <0x01>;
				#size-cells = <0x00>;

				port@0 {
					reg = <0x00>;

					endpoint {
						remote-endpoint = <0x22>;
						phandle = <0x25>;
					};
				};
			};
		};

		atk_lcd_drm {
			compatible = "atk,atk_dpi";
			status = "okay";
			clocks = <0x08 0x00>;
			clock-names = "lcd_pclk";
			pwms = <0x23 0x00 0x4c4b40>;
			lcdID = <0x24 0x00 0x00 0x01 0x24 0x01 0x00 0x01 0x24 0x02 0x00 0x01>;

			ports {
				#address-cells = <0x01>;
				#size-cells = <0x00>;

				port@0 {
					reg = <0x00>;

					endpoint {
						remote-endpoint = <0x25>;
						phandle = <0x22>;
					};
				};
			};

			display-timings {

				timing0 {
					clock-frequency = <0x895440>;
					hactive = <0x1e0>;
					vactive = <0x110>;
					hback-porch = <0x02>;
					hfront-porch = <0x02>;
					hsync-len = <0x29>;
					vback-porch = <0x02>;
					vfront-porch = <0x02>;
					vsync-len = <0x0a>;
					hsync-active = <0x00>;
					vsync-active = <0x00>;
					de-active = <0x01>;
					phandle = <0x52>;
				};

				timing1 {
					clock-frequency = <0x1fc9350>;
					hactive = <0x320>;
					vactive = <0x1e0>;
					hback-porch = <0x58>;
					hfront-porch = <0x28>;
					hsync-len = <0x80>;
					vback-porch = <0x21>;
					vfront-porch = <0x0a>;
					vsync-len = <0x02>;
					hsync-active = <0x00>;
					vsync-active = <0x00>;
					de-active = <0x01>;
					pixelclk-active = <0x00>;
					phandle = <0x53>;
				};

				timing2 {
					clock-frequency = <0x30d4000>;
					hactive = <0x400>;
					vactive = <0x258>;
					hback-porch = <0x8c>;
					hfront-porch = <0xa0>;
					hsync-len = <0x14>;
					vback-porch = <0x14>;
					vfront-porch = <0x0c>;
					vsync-len = <0x03>;
					hsync-active = <0x00>;
					vsync-active = <0x00>;
					de-active = <0x01>;
					pixelclk-active = <0x00>;
					phandle = <0x54>;
				};

				timing3 {
					clock-frequency = <0x43ce660>;
					hactive = <0x500>;
					vactive = <0x320>;
					hback-porch = <0x50>;
					hfront-porch = <0x46>;
					hsync-len = <0x0a>;
					vback-porch = <0x0a>;
					vfront-porch = <0x0a>;
					vsync-len = <0x03>;
					hsync-active = <0x00>;
					vsync-active = <0x00>;
					de-active = <0x01>;
					pixelclk-active = <0x00>;
					phandle = <0x55>;
				};
			};
		};

		drm_pl_disp_hdmi {
			compatible = "xlnx,pl-disp";
			dmas = <0x26 0x00>;
			dma-names = "dma0";
			xlnx,vformat = "BG24";
			xlnx,bridge = <0x27>;

			ports {
				#address-cells = <0x01>;
				#size-cells = <0x00>;

				port@0 {
					reg = <0x00>;

					endpoint {
						remote-endpoint = <0x28>;
						phandle = <0x2b>;
					};
				};
			};
		};

		atk_hdmi_drm {
			compatible = "atk,atk-hdmi";
			status = "okay";
			clocks = <0x29 0x00 0x29 0x01>;
			clock-names = "hdmi_pclk\0hdmi_pclk_5x";
			clk-num = <0x02>;
			ddc-i2c-bus = <0x2a>;
			hpd-gpios = <0x09 0x40 0x00>;

			ports {
				#address-cells = <0x01>;
				#size-cells = <0x00>;

				port@0 {
					reg = <0x00>;

					endpoint {
						remote-endpoint = <0x2b>;
						phandle = <0x28>;
					};
				};
			};
		};

		vcap_dvp {
			compatible = "xlnx,video";
			dmas = <0x2c 0x00>;
			dma-names = "port0";
			status = "okay";

			ports {
				#address-cells = <0x01>;
				#size-cells = <0x00>;

				port@0 {
					reg = <0x00>;
					direction = "input";

					endpoint {
						remote-endpoint = <0x2d>;
						phandle = <0x1e>;
					};
				};
			};
		};

		gpio@80010000 {
			compatible = "xlnx,axi-gpio-2.0\0xlnx,xps-gpio-1.00.a";
			reg = <0x80010000 0x10000>;
			#gpio-cells = <0x03>;
			gpio-controller;
			clock-names = "s_axi_aclk";
			clocks = <0x01 0x0f>;
			xlnx,gpio-width = <0x01>;
			xlnx,is-dual = <0x00>;
			xlnx,all-inputs = <0x00>;
			xlnx,all-outputs = <0x01>;
			xlnx,dout-default = <0x00>;
			xlnx,tri-default = <0x00>;
			xlnx,interrupt-present = <0x00>;
			status = "okay";
			phandle = <0x56>;
		};

		keypoint-conv@80000000 {
			compatible = "gesture,keypoint-conv-f32-v1";
			reg = <0x80000000 0x10000>;
			clock-names = "ap_clk";
			clocks = <0x01 0x0f>;
			reset-gpios = <0x56 0x00 0x00 0x01>;
			interrupt-parent = <0x04>;
			interrupts = <0x00 0x36 0x04>;
			status = "okay";
			phandle = <0x57>;
		};
	};

	chosen {
		bootargs = "console=ttyPS0,115200 cma=128M earlycon root=/dev/mmcblk0p2 rw rootwait";
		stdout-path = "serial0:115200n8";
	};

	aliases {
		ethernet0 = "/amba/ethernet@e000b000";
		ethernet1 = "/amba/ethernet@e000c000";
		i2c0 = "/amba_pl/i2c@41600000";
		i2c1 = "/amba/i2c@e0004000";
		i2c2 = "/amba/i2c@e0005000";
		serial0 = "/amba/serial@e0000000";
		serial1 = "/amba/serial@e0001000";
		spi0 = "/amba/spi@e000d000";
	};

	memory {
		device_type = "memory";
		reg = <0x00 0x40000000>;
	};

	leds {
		compatible = "gpio-leds";

		gpio-led1 {
			label = "led1";
			gpios = <0x09 0x36 0x00>;
			default-state = "on";
		};

		gpio-led2 {
			label = "led2";
			gpios = <0x09 0x00 0x00>;
			linux,default-trigger = "heartbeat";
		};

		gpio-led3 {
			label = "pl_led0";
			gpios = <0x2e 0x00 0x00 0x00>;
			default-state = "on";
		};

		gpio-led4 {
			label = "pl_led1";
			gpios = <0x2e 0x01 0x00 0x00>;
			linux,default-trigger = "timer";
		};

		gpio-led5 {
			label = "ps_led0";
			gpios = <0x09 0x07 0x00>;
			default-state = "on";
		};

		gpio-led6 {
			label = "ps_led1";
			gpios = <0x09 0x08 0x00>;
			linux,default-trigger = "timer";
		};
	};

	keys {
		compatible = "gpio-keys";
		autorepeat;

		gpio-key1 {
			label = "pl_key0";
			gpios = <0x09 0x37 0x01>;
			linux,code = <0x69>;
			gpio-key,wakeup;
			autorepeat;
		};

		gpio-key2 {
			label = "pl_key1";
			gpios = <0x09 0x38 0x01>;
			linux,code = <0x6a>;
			gpio-key,wakeup;
			autorepeat;
		};

		gpio-key3 {
			label = "ps_key1";
			gpios = <0x09 0x0c 0x01>;
			linux,code = <0x67>;
			gpio-key,wakeup;
			autorepeat;
		};

		gpio-key4 {
			label = "ps_key2";
			gpios = <0x09 0x0b 0x01>;
			linux,code = <0x6c>;
			gpio-key,wakeup;
			autorepeat;
		};

		touch-key {
			label = "touch_key";
			gpios = <0x09 0x39 0x00>;
			linux,code = <0x1c>;
			gpio-key,wakeup;
			autorepeat;
		};
	};

	beep {
		compatible = "gpio-beeper";
		gpios = <0x09 0x3a 0x00>;
	};

	phy0@e0002000 {
		compatible = "ulpi-phy";
		#phy-cells = <0x00>;
		reg = <0xe0002000 0x1000>;
		view-port = <0x170>;
		drv-vbus;
		phandle = <0x0d>;
	};

	__symbols__ {
		cpu0 = "/cpus/cpu@0";
		cpu1 = "/cpus/cpu@1";
		fpga_full = "/fpga-full";
		regulator_vccpint = "/fixedregulator";
		replicator_out_port0 = "/replicator/out-ports/port@0/endpoint";
		replicator_out_port1 = "/replicator/out-ports/port@1/endpoint";
		replicator_in_port0 = "/replicator/in-ports/port/endpoint";
		amba = "/amba";
		adc = "/amba/adc@f8007100";
		can0 = "/amba/can@e0008000";
		can1 = "/amba/can@e0009000";
		gpio0 = "/amba/gpio@e000a000";
		i2c0 = "/amba/i2c@e0004000";
		codec = "/amba/i2c@e0004000/wm8960@1a";
		i2c1 = "/amba/i2c@e0005000";
		intc = "/amba/interrupt-controller@f8f01000";
		L2 = "/amba/cache-controller@f8f02000";
		mc = "/amba/memory-controller@f8006000";
		ocmc = "/amba/ocmc@f800c000";
		uart0 = "/amba/serial@e0000000";
		uart1 = "/amba/serial@e0001000";
		spi0 = "/amba/spi@e0006000";
		spi1 = "/amba/spi@e0007000";
		qspi = "/amba/spi@e000d000";
		smcc = "/amba/memory-controller@e000e000";
		nand0 = "/amba/memory-controller@e000e000/flash@e1000000";
		nor0 = "/amba/memory-controller@e000e000/flash@e2000000";
		gem0 = "/amba/ethernet@e000b000";
		ethernet_phy = "/amba/ethernet@e000b000/ethernet-phy@7";
		gem1 = "/amba/ethernet@e000c000";
		pl_phy = "/amba/ethernet@e000c000/pl_phy@4";
		sdhci0 = "/amba/mmc@e0100000";
		sdhci1 = "/amba/mmc@e0101000";
		slcr = "/amba/slcr@f8000000";
		clkc = "/amba/slcr@f8000000/clkc@100";
		rstc = "/amba/slcr@f8000000/rstc@200";
		pinctrl0 = "/amba/slcr@f8000000/pinctrl@700";
		dmac_s = "/amba/dmac@f8003000";
		devcfg = "/amba/devcfg@f8007000";
		efuse = "/amba/efuse@f800d000";
		global_timer = "/amba/timer@f8f00200";
		ttc0 = "/amba/timer@f8001000";
		ttc1 = "/amba/timer@f8002000";
		scutimer = "/amba/timer@f8f00600";
		usb0 = "/amba/usb@e0002000";
		usb1 = "/amba/usb@e0003000";
		watchdog0 = "/amba/watchdog@f8005000";
		etb_in_port = "/amba/etb@f8801000/in-ports/port/endpoint";
		tpiu_in_port = "/amba/tpiu@f8803000/in-ports/port/endpoint";
		funnel_out_port = "/amba/funnel@f8804000/out-ports/port/endpoint";
		funnel0_in_port0 = "/amba/funnel@f8804000/in-ports/port@0/endpoint";
		funnel0_in_port1 = "/amba/funnel@f8804000/in-ports/port@1/endpoint";
		funnel0_in_port2 = "/amba/funnel@f8804000/in-ports/port@2/endpoint";
		ptm0_out_port = "/amba/ptm@f889c000/out-ports/port/endpoint";
		ptm1_out_port = "/amba/ptm@f889d000/out-ports/port/endpoint";
		amba_pl = "/amba_pl";
		audio_audio_formatter = "/amba_pl/audio_formatter@43c50000";
		misc_clk_0 = "/amba_pl/misc_clk_0";
		audio_i2s_receiver = "/amba_pl/i2s_receiver@43c60000";
		audio_i2s_transmitter = "/amba_pl/i2s_transmitter@43c70000";
		axi_gpio_0 = "/amba_pl/gpio@41210000";
		camera_in_v_frmbuf_wr_0 = "/amba_pl/v_frmbuf_wr@43c40000";
		clk_wiz_0 = "/amba_pl/clk_wiz@43c30000";
		hdmi_out_clk_wiz_dyn = "/amba_pl/clk_wiz@43c80000";
		hdmi_out_hdmi_vtc = "/amba_pl/v_tc@43c90000";
		misc_clk_1 = "/amba_pl/misc_clk_1";
		hdmi_out_v_frmbuf_rd_0 = "/amba_pl/v_frmbuf_rd@43ca0000";
		i2c2 = "/amba_pl/i2c@41600000";
		ov5640_ep = "/amba_pl/i2c@41600000/ov5640@3c/port@0/endpoint";
		lcd_out_lcd_id = "/amba_pl/gpio@41200000";
		lcd_out_lcd_pl_pwm = "/amba_pl/PWM@43c00000";
		lcd_out_lcd_vtc = "/amba_pl/v_tc@43c10000";
		misc_clk_2 = "/amba_pl/misc_clk_2";
		lcd_out_v_frmbuf_rd_0 = "/amba_pl/v_frmbuf_rd@43c20000";
		rest_gpio = "/amba_pl/gpio@41220000";
		pl_disp_crtc_lcd = "/amba_pl/drm_pl_disp_lcd/ports/port@0/endpoint";
		lcd_encoder = "/amba_pl/atk_lcd_drm/ports/port@0/endpoint";
		timing_4342 = "/amba_pl/atk_lcd_drm/display-timings/timing0";
		timing_7084 = "/amba_pl/atk_lcd_drm/display-timings/timing1";
		timing_7016 = "/amba_pl/atk_lcd_drm/display-timings/timing2";
		timing_1018 = "/amba_pl/atk_lcd_drm/display-timings/timing3";
		pl_disp_crtc_hdmi = "/amba_pl/drm_pl_disp_hdmi/ports/port@0/endpoint";
		hdmi_encoder = "/amba_pl/atk_hdmi_drm/ports/port@0/endpoint";
		xlnx_vcap = "/amba_pl/vcap_dvp/ports/port@0/endpoint";
		usb_phy0 = "/phy0@e0002000";
	};
};
